# M3351 register map
File version: 1.0
Registers are 32-bit, read-write, reset 0x0 unless marked. A register's access mark holds for its fields unless they carry their own. Offsets are from the block's base; [hi:lo] are bit positions.

## DFMC — DFMC Register Map
Base 0x4000F000
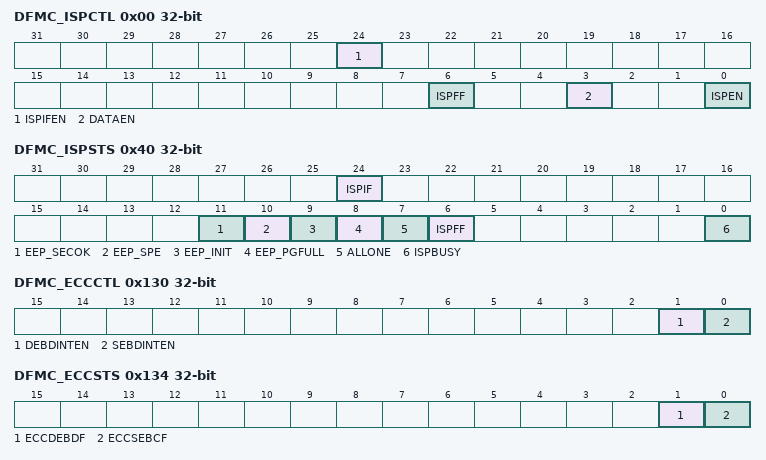
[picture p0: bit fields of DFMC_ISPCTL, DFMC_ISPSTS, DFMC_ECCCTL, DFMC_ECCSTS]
0x00 DFMC_ISPCTL — ISP Control Register
  [24] ISPIFEN — ISP Interrupt Enable bit (Write Protect). Note: This bit is write protected. Refer to the SYS_REGLCTL register.
    0=ISP Interrupt Disabled; 1=ISP Interrupt Enabled
  [6] ISPFF — ISP Fail Flag (Write Protect). This bit is set by hardware when a triggered ISP meets any of the following conditions: This bit needs to be cleared by writing 1 to it. Data Flash writes to itself if DATAEN is set to 0. Erase or Program command at brown-out detected. Destination address is illegal, such as exceeding an available range. Invalid ISP commands. Violate the load code read protection. Checksum or Flash All One Verification is not executed in their valid range. Mass erase is not executed in Data Flash. Note: This bit is write protected. Refer to the SYS_REGLCTL register.
  [3] DATAEN — Data Flash Update Enable Bit (Write Protect). Note: This bit is write protected. Refer to the SYS_REGLCTL register.
    0=Data Flash cannot be updated; 1=Data Flash can be updated
  [0] ISPEN — ISP Enable Bit (Write Protect). ISP function enable bit. Set this bit to enable ISP function. Note: This bit is write protected. Refer to the SYS_REGLCTL register.
    0=ISP function Disabled; 1=ISP function Enabled
0x04 DFMC_ISPADDR — ISP Address Register
  [31:0] ISPADDR — ISP Address. The M3351 is equipped with embedded Data Flash. ISPADDR[1:0] must be kept 00 for ISP 32-bit operation. For CRC32 Checksum Calculation command, this field is the Data Flash starting address for checksum calculation, 4 Kbytes alignment is necessary for CRC32 checksum calculation. For Data Flash32-bit Program, ISP address needs word alignment (4-byte).
0x08 DFMC_ISPDAT — ISP Data Register
  [31:0] ISPDAT — ISP Data. Write data to this register before ISP program operation. Read data from this register after ISP read operation.
0x0C DFMC_ISPCMD — ISP Command Register
  [6:0] CMD — ISP Command. ISP command table is shown below: The other commands are invalid.
    0=Data FLASH Read; 8=Read Data Flash All-One Result; 11=Read Company ID; 12=Read Device ID; 13=Read Checksum; 33=Data FLASH 32-bit Program; 34=Data FLASH Page Erase. Erase any page in Data Flash; 38=Data FLASH Mass Erase. Erase all pages in Data Flash; 40=Run Data Flash All-One Verification; 45=Run Checksum Calculation; 48=EEPROM emulation 32 bit read; 49=EEPROM emulation 8 bit program; 50=EEPROM emulation 32 bit program; 51=EEPROM emulation initial
0x10 DFMC_ISPTRG — ISP Trigger Control Register
  [0] ISPGO — ISP Start Trigger (Write Protect). Write 1 to start ISP operation and this bit will be cleared to 0 by hardware automatically when ISP operation is finished. Note: This bit is write protected. Refer to the SYS_REGLCTL register.
    0=ISP operation is finished; 1=ISP is progressed
0x40 DFMC_ISPSTS — ISP Status Register
  [24] ISPIF — ISP Interrupt Flag (Write Protect). Note: Write 1 to clear this bit.
    0=ISP command not finish or ISP fail flag is 0; 1=ISP command finish or ISP fail is 1
  [11] EEP_SECOK — EEPROM Emulation Active and Secure Region Status (Read Only). This bit is set by hardware when EEPROM emulation is enabled and the region is marked as Secure.
    0=Not in EEPROM Secure Mode; 1=In EEPROM Secure Mode
  [10] EEP_SPE — EEPROM Emulation SRAM Pairty check error (Write Protect)
    0=No SRAM parity check error; 1=SRAM parity check error detected
  [9] EEP_INIT — EEPROM Emulation in the initial processing
    0=EEPROM initialization not done; 1=EEPROM initialization done
  [8] EEP_PGFULL — EEPROM Emulation in the page full processing. This bit is set by hardware if EEPROM program and Flash page full. EEPROM emulation will automatic start the page full processing it need program current EEPPROM emulation SRAM data to next page and Erase current page.
    0=Not in page full processing; 1=in the page full processing
  [7] ALLONE — Data Flash All-one Verification Flag. This bit is set by hardware if all of Flash bits are 1, and clear if Flash bits are not all 1 after 'Run Data Flash All-One Verification' complete; this bit also can be clear by writing 1
    0=Data Flash bits are not all 1 after 'Run Data Flash All-One Verification' is complete; 1=All of Data Flash bits are 1 after 'Run Data Flash All-One Verification' is complete
  [6] ISPFF — ISP Fail Flag (Write Protect). This bit is the mirror of ISPFF (DFMC_ISPCTL[6]), it needs to be cleared by writing 1 to DFMC_ISPCTL[6] or DFMC_ISPSTS[6]. This bit is set by hardware when a triggered ISP meets any of the following conditions: Data Flash writes to itself if DATAEN is set to 0. Erase or Program command at brown-out detected. Destination address is illegal, such as exceeding an available range. Invalid ISP commands. Violate the load code read protection. Checksum or Flash All One Verification is not executed in their valid range. Mass erase is not executed in Data Flash. Note: This bit is write protected. Refer to the SYS_REGLCTL register.
  [0] ISPBUSY — ISP Busy Flag (Read Only). Write 1 to start ISP operation and this bit will be cleared to 0 by hardware automatically when ISP operation is finished. This bit is the mirror of ISPGO(DFMC_ISPTRG[0]).
    0=ISP operation is finished; 1=ISP is progressed
0x4C DFMC_CYCCTL reset 0x1 — Data Flash Access Cycle Control Register
  [3:0] CYCLE — Data Flash Access Cycle Control (Write Protect). This register is updated by software. The optimized HCLK working frequency range is 135~144 MHz. Note: This bit is write protected. Refer to the SYS_REGLCTL register.
    0=CPU access with zero wait cycle ; Flash access cycle is 1;; 1=CPU access with one wait cycle if cache miss; Flash access cycle is 1;; 2=CPU access with two wait cycles if cache miss; Flash access cycle is 2;; 3=CPU access with three wait cycles if cache miss; Flash access cycle is 3;; 4=CPU access with four wait cycles if cache miss; Flash access cycle is 4;; 5=CPU access with five wait cycles if cache miss; Flash access cycle is 5;; 6=CPU access with six wait cycles if cache miss; Flash access cycle is 6;
0x90 DFMC_MPDATE — ISP Data Error Register
  [6:0] ISPDATE — ISP Data Error Register. Read data from this register after ISP 32-bit read operation or ECCSEBCF(DFMC_ECCSTS[0]) is high can know which bit is error. ISPDATE does not continuously store the position information of ECC errors. Therefore, if the user wants to know which bit generated the error, they need to read it before the next ISP action after an ECC single-bit error occurs, or access that position again. This register is the ECC 7-bit data. Note: This bit is only by ISP read commands when an ECC error occurs.
0x130 DFMC_ECCCTL — DFMC Error Code Correction Control
  [1] DEBDINTEN — Double Error Bits Detection Interrupt Enable (Write Protect). Note: This bit is write protected. Refer to the SYS_REGLCTL register.
    0=Double Error Bits Detection Interrupt Disabled; 1=Double Error Bits Detection Interrupt Enabled
  [0] SEBDINTEN — Single Error Bits Detection Interrupt Enable (Write Protect). Note: This bit is write protected. Refer to the SYS_REGLCTL register.
    0=Single Error Bit Detection Interrupt Disabled; 1=Single Error Bit Detection Interrupt Enabled
0x134 DFMC_ECCSTS — DFMC Error Code Correction status
  [1] ECCDEBDF — ECC Double Error Bits Detection Flag
    0=DFMC does not detect ECC double error bits fault; 1=DFMC detects ECC double error bits fault
  [0] ECCSEBCF — ECC Single Error Bits Correction Flag
    0=DFMC does not detect ECC single error bits fault; 1=DFMC detects and corrects ECC single error bits fault
0x138 DFMC_ECCSEFAR ro — DFMC ECC Single Error fault Adress Register
  [31:0] ECCSEFAR — ECC Single Error Fault Address Register (Read Only). When DFMC detects a ECCSEBCF(DFMC_ECCSTS[0]) would record fault address at the register. The register is cleared by writing 1 to ECCSEBCF. ECCSEFAR returns the CPU read address, so the lowest two bits of the address may not be zero and should be ignored. Note: During ISP commands 0x0D or 0x08, this register keeps the CRC/All-One check error value captured at that moment.
0x13C DFMC_ECCDEFAR ro — DFMC ECC Double Error fault Adress Register
  [31:0] ECCDEFAR — ECC Double Error Fault Address Register (Read Only). When DFMC detects a ECCDEBDF(DFMC_ECCSTS[1]) would record fault address at the register. The register is cleared by writing 1 to ECCDEBDF. ECCDEFAR returns the CPU read address, so the lowest two bits of the address may not be zero and should be ignored. Note: During ISP commands 0x0D or 0x08, this register keeps the CRC/All-One check error value captured at that moment.
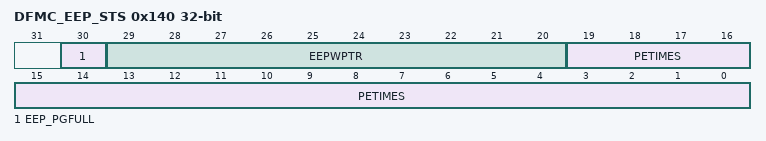
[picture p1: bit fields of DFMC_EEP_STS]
0x140 DFMC_EEP_STS ro — DFMC EEPROM Emulation Status Register
  [30] EEP_PGFULL — EEPROM Emulation in the page full processing. This bit is set by hardware if EEPROM program and Flash page full. EEPROM emulation will automatic start the page full processing it need program current EEPPROM emulation SRAM data to next page and Erase current page.
    0=Not in page full processing; 1=In the page full processing
  [29:20] EEPWPTR — Current Page Write Pointer
  [19:0] PETIMES — Page erase times. Two EEPROM eumlation total erase times.The number is two pages total, So if the number is 100 it means each page erase 50 times.
